VERSION ""

NS_ :

BS_:

BU_: DBG SENDER RECEIVER

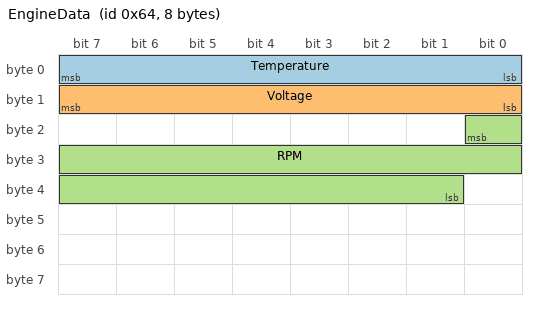
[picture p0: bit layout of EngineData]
BO_ 100 EngineData: 8 SENDER
 SG_ Temperature : 0|8@1+ (1,-40) [-40|215] "C" RECEIVER
 SG_ Voltage : 8|8@1+ (0.1,0) [0|25] "V" RECEIVER
 SG_ RPM : 16|16@0+ (1,0) [0|10000] "rpm" RECEIVER
